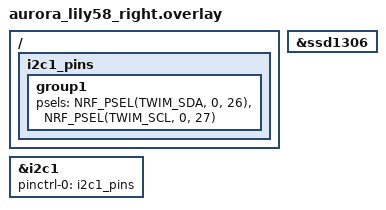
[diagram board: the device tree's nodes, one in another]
/ {
    i2c1_pins: i2c1_pins {
        group1 {
            psels = <NRF_PSEL(TWIM_SDA, 0, 26)>, <NRF_PSEL(TWIM_SCL, 0, 27)>;
        };
    };
};

&i2c1 {
    pinctrl-0 = <&i2c1_pins>;
    pinctrl-names = "default";
    status = "okay";
};

&ssd1306 {
    status = "okay";
};
